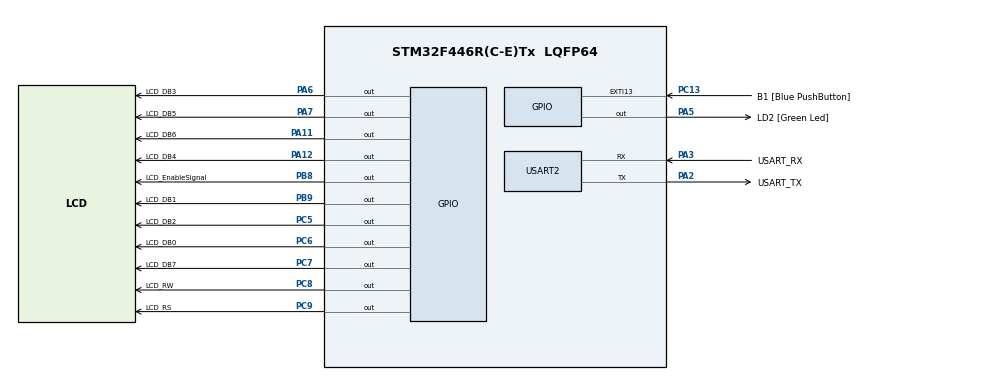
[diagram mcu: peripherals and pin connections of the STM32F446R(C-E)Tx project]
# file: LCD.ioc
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Mcu.Family=STM32F4
PH0-OSC_IN.Signal=RCC_OSC_IN
RCC.CortexFreq_Value=84000000
PA14.GPIO_Label=TCK
PC6.GPIO_Label=LCD_DB0
PA6.GPIO_Label=LCD_DB3
PC13.GPIO_Label=B1 [Blue PushButton]
RCC.SYSCLKSource=RCC_SYSCLKSOURCE_PLLCLK
ProjectManager.StackSize=0x400
PA12.Signal=GPIO_Output
RCC.HCLKFreq_Value=84000000
RCC.APB2TimFreq_Value=84000000
PC7.Signal=GPIO_Output
RCC.AHBFreq_Value=84000000
PH0-OSC_IN.Mode=HSE-External-Oscillator
RCC.HSE_VALUE=8000000
PC14-OSC32_IN.Mode=LSE-External-Oscillator
PA14.Mode=Serial_Wire
RCC.FLatency-AdvancedSettings=FLASH_LATENCY_2
PH1-OSC_OUT.Mode=HSE-External-Oscillator
PB9.Signal=GPIO_Output
Mcu.Package=LQFP64
PA6.Signal=GPIO_Output
USART2.VirtualMode=VM_ASYNC
PA2.GPIO_Label=USART_TX
RCC.APB1TimFreq_Value=84000000
PC5.Signal=GPIO_Output
PA3.Signal=USART2_RX
PB3.GPIO_Label=SWO
PC15-OSC32_OUT.Mode=LSE-External-Oscillator
PB9.GPIO_Label=LCD_DB1
PC9.GPIO_Label=LCD_RS
PC13.Signal=GPXTI13
PC8.Signal=GPIO_Output
PC6.Signal=GPIO_Output
PA11.GPIO_Label=LCD_DB6
RCC.APB1CLKDivider=RCC_HCLK_DIV2
PC14-OSC32_IN.Signal=RCC_OSC32_IN
PA12.GPIO_Label=LCD_DB4
PC8.GPIO_Label=LCD_RW
PA3.Mode=Asynchronous
PA13.Signal=SYS_JTMS-SWDIO
PB8.GPIO_Label=LCD_EnableSignal
ProjectManager.TargetToolchain=STM32CubeIDE
RCC.USBFreq_Value=168000000
PC15-OSC32_OUT.Signal=RCC_OSC32_OUT
PA5.Signal=GPIO_Output
board=NUCLEO-F446RE
RCC.VCOOutputFreq_Value=336000000
RCC.APB2Freq_Value=84000000
PH1-OSC_OUT.Signal=RCC_OSC_OUT
PA13.Mode=Serial_Wire
Mcu.Name=STM32F446R(C-E)Tx
PA13.GPIO_Label=TMS
PA2.Signal=USART2_TX
PC7.GPIO_Label=LCD_DB7
RCC.48MHZClocksFreq_Value=84000000
PB3.Signal=SYS_JTDO-SWO
RCC.SYSCLKFreq_VALUE=84000000
PA7.GPIO_Label=LCD_DB5
PA5.GPIO_Label=LD2 [Green Led]
PC13.GPIO_ModeDefaultEXTI=GPIO_MODE_IT_FALLING
PC5.GPIO_Label=LCD_DB2
PA11.Signal=GPIO_Output
PA14.Signal=SYS_JTCK-SWCLK
ProjectManager.HeapSize=0x200
RCC.HSI_VALUE=16000000
RCC.PLLP=RCC_PLLP_DIV4
NVIC.PriorityGroup=NVIC_PRIORITYGROUP_0
RCC.PLLN=336
PA2.Mode=Asynchronous
PB8.Signal=GPIO_Output
PC9.Signal=GPIO_Output
RCC.APB1Freq_Value=42000000
PA3.GPIO_Label=USART_RX
PA7.Signal=GPIO_Output

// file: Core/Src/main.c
/* USER CODE BEGIN Header */
/**
  ******************************************************************************
  * @file           : main.c
  * @brief          : Main program body
  ******************************************************************************
  * @attention
  *
  * <h2><center>&copy; Copyright (c) 2021 STMicroelectronics.
  * All rights reserved.</center></h2>
  *
  * This software component is licensed by ST under BSD 3-Clause license,
  * the "License"; You may not use this file except in compliance with the
  * License. You may obtain a copy of the License at:
  *                        opensource.org/licenses/BSD-3-Clause
  *
  ******************************************************************************
  */
/* USER CODE END Header */
#include "main.h"

/* USER CODE BEGIN Includes */

#include "LCD.h"

/* USER CODE END Includes */

UART_HandleTypeDef huart2;

void SystemClock_Config (void);
static void MX_GPIO_Init (void);
static void MX_USART2_UART_Init (void);

int main (void)
{

/* Reset of all peripherals, Initializes the Flash interface and the Systick. */
    HAL_Init ();

/* Configure the system clock */
    SystemClock_Config ();

/* Initialize all configured peripherals */
    MX_GPIO_Init ();
    MX_USART2_UART_Init ();
/* USER CODE BEGIN 2 */

    LCD_Init ();

    char *text = "Lorem ipsum";

//    uint8_t charmap[] =
//        { 4, 14, 27, 14, 20, 13, 6, 4 };
//
//    LCD_BuildCustomChar (0, charmap);
//    LCD_SetCursor (0, 0);

/* USER CODE END 2 */

/* Infinite loop */
    while (1)
    {

        LCD_WriteText ((uint8_t*) text);
        LCD_Clear ();

//        for (int i = 0; i < LCD_SIZE; ++i)
//        {
//            if (i == LCD_SIZE / 2)
//            {
//                LCD_SetCursor (0, 1);
//            }
//
//            LCD_WriteChar (0);
//            HAL_Delay (1000);
//        }
//
//        LCD_Clear ();

    }
}

void SystemClock_Config (void)
{
    RCC_OscInitTypeDef RCC_OscInitStruct =
        { 0 };
    RCC_ClkInitTypeDef RCC_ClkInitStruct =
        { 0 };

/** Configure the main internal regulator output voltage
  */
    __HAL_RCC_PWR_CLK_ENABLE();
    __HAL_PWR_VOLTAGESCALING_CONFIG(PWR_REGULATOR_VOLTAGE_SCALE3);
/** Initializes the RCC Oscillators according to the specified parameters
  * in the RCC_OscInitTypeDef structure.
  */
    RCC_OscInitStruct.OscillatorType = RCC_OSCILLATORTYPE_HSI;
    RCC_OscInitStruct.HSIState = RCC_HSI_ON;
    RCC_OscInitStruct.HSICalibrationValue = RCC_HSICALIBRATION_DEFAULT;
    RCC_OscInitStruct.PLL.PLLState = RCC_PLL_ON;
    RCC_OscInitStruct.PLL.PLLSource = RCC_PLLSOURCE_HSI;
    RCC_OscInitStruct.PLL.PLLM = 16;
    RCC_OscInitStruct.PLL.PLLN = 336;
    RCC_OscInitStruct.PLL.PLLP = RCC_PLLP_DIV4;
    RCC_OscInitStruct.PLL.PLLQ = 2;
    RCC_OscInitStruct.PLL.PLLR = 2;
    if (HAL_RCC_OscConfig (&RCC_OscInitStruct) != HAL_OK)
    {
        Error_Handler ();
    }
/** Initializes the CPU, AHB and APB buses clocks
  */
    RCC_ClkInitStruct.ClockType = RCC_CLOCKTYPE_HCLK | RCC_CLOCKTYPE_SYSCLK
            | RCC_CLOCKTYPE_PCLK1 | RCC_CLOCKTYPE_PCLK2;
    RCC_ClkInitStruct.SYSCLKSource = RCC_SYSCLKSOURCE_PLLCLK;
    RCC_ClkInitStruct.AHBCLKDivider = RCC_SYSCLK_DIV1;
    RCC_ClkInitStruct.APB1CLKDivider = RCC_HCLK_DIV2;
    RCC_ClkInitStruct.APB2CLKDivider = RCC_HCLK_DIV1;

    if (HAL_RCC_ClockConfig (&RCC_ClkInitStruct, FLASH_LATENCY_2) != HAL_OK)
    {
        Error_Handler ();
    }
}

static void MX_USART2_UART_Init (void)
{

    huart2.Instance = USART2;
    huart2.Init.BaudRate = 115200;
    huart2.Init.WordLength = UART_WORDLENGTH_8B;
    huart2.Init.StopBits = UART_STOPBITS_1;
    huart2.Init.Parity = UART_PARITY_NONE;
    huart2.Init.Mode = UART_MODE_TX_RX;
    huart2.Init.HwFlowCtl = UART_HWCONTROL_NONE;
    huart2.Init.OverSampling = UART_OVERSAMPLING_16;
    if (HAL_UART_Init (&huart2) != HAL_OK)
    {
        Error_Handler ();
    }

}

static void MX_GPIO_Init (void)
{
    GPIO_InitTypeDef GPIO_InitStruct =
        { 0 };

/* GPIO Ports Clock Enable */
    __HAL_RCC_GPIOC_CLK_ENABLE();
    __HAL_RCC_GPIOH_CLK_ENABLE();
    __HAL_RCC_GPIOA_CLK_ENABLE();
    __HAL_RCC_GPIOB_CLK_ENABLE();

/*Configure GPIO pin Output Level */
    HAL_GPIO_WritePin (GPIOA,
    LD2_Pin | LCD_DB3_Pin | LCD_DB5_Pin | LCD_DB6_Pin | LCD_DB4_Pin,
                       GPIO_PIN_RESET);

/*Configure GPIO pin Output Level */
    HAL_GPIO_WritePin (GPIOC,
    LCD_DB2_Pin | LCD_DB0_Pin | LCD_DB7_Pin | LCD_RW_Pin | LCD_RS_Pin,
                       GPIO_PIN_RESET);

/*Configure GPIO pin Output Level */
    HAL_GPIO_WritePin (GPIOB,
    LCD_EnableSignal_Pin | LCD_DB1_Pin,
                       GPIO_PIN_RESET);

/*Configure GPIO pin : B1_Pin */
    GPIO_InitStruct.Pin = B1_Pin;
    GPIO_InitStruct.Mode = GPIO_MODE_IT_FALLING;
    GPIO_InitStruct.Pull = GPIO_NOPULL;
    HAL_GPIO_Init (B1_GPIO_Port, &GPIO_InitStruct);

/*Configure GPIO pins : LD2_Pin LCD_DB3_Pin LCD_DB5_Pin LCD_DB6_Pin
                           LCD_DB4_Pin */
    GPIO_InitStruct.Pin = LD2_Pin | LCD_DB3_Pin | LCD_DB5_Pin | LCD_DB6_Pin
            | LCD_DB4_Pin;
    GPIO_InitStruct.Mode = GPIO_MODE_OUTPUT_PP;
    GPIO_InitStruct.Pull = GPIO_NOPULL;
    GPIO_InitStruct.Speed = GPIO_SPEED_FREQ_LOW;
    HAL_GPIO_Init (GPIOA, &GPIO_InitStruct);

/*Configure GPIO pins : LCD_DB2_Pin LCD_DB0_Pin LCD_DB7_Pin LCD_RW_Pin
                           LCD_RS_Pin */
    GPIO_InitStruct.Pin = LCD_DB2_Pin | LCD_DB0_Pin | LCD_DB7_Pin | LCD_RW_Pin
            | LCD_RS_Pin;
    GPIO_InitStruct.Mode = GPIO_MODE_OUTPUT_PP;
    GPIO_InitStruct.Pull = GPIO_NOPULL;
    GPIO_InitStruct.Speed = GPIO_SPEED_FREQ_LOW;
    HAL_GPIO_Init (GPIOC, &GPIO_InitStruct);

/*Configure GPIO pins : LCD_EnableSignal_Pin LCD_DB1_Pin */
    GPIO_InitStruct.Pin = LCD_EnableSignal_Pin | LCD_DB1_Pin;
    GPIO_InitStruct.Mode = GPIO_MODE_OUTPUT_PP;
    GPIO_InitStruct.Pull = GPIO_NOPULL;
    GPIO_InitStruct.Speed = GPIO_SPEED_FREQ_LOW;
    HAL_GPIO_Init (GPIOB, &GPIO_InitStruct);

}

void Error_Handler (void)
{
/* USER CODE BEGIN Error_Handler_Debug */
/* User can add his own implementation to report the HAL error return state */
    __disable_irq ();
    while (1)
    {
    }
/* USER CODE END Error_Handler_Debug */
}

/************************ (C) COPYRIGHT STMicroelectronics *****END OF FILE****/
